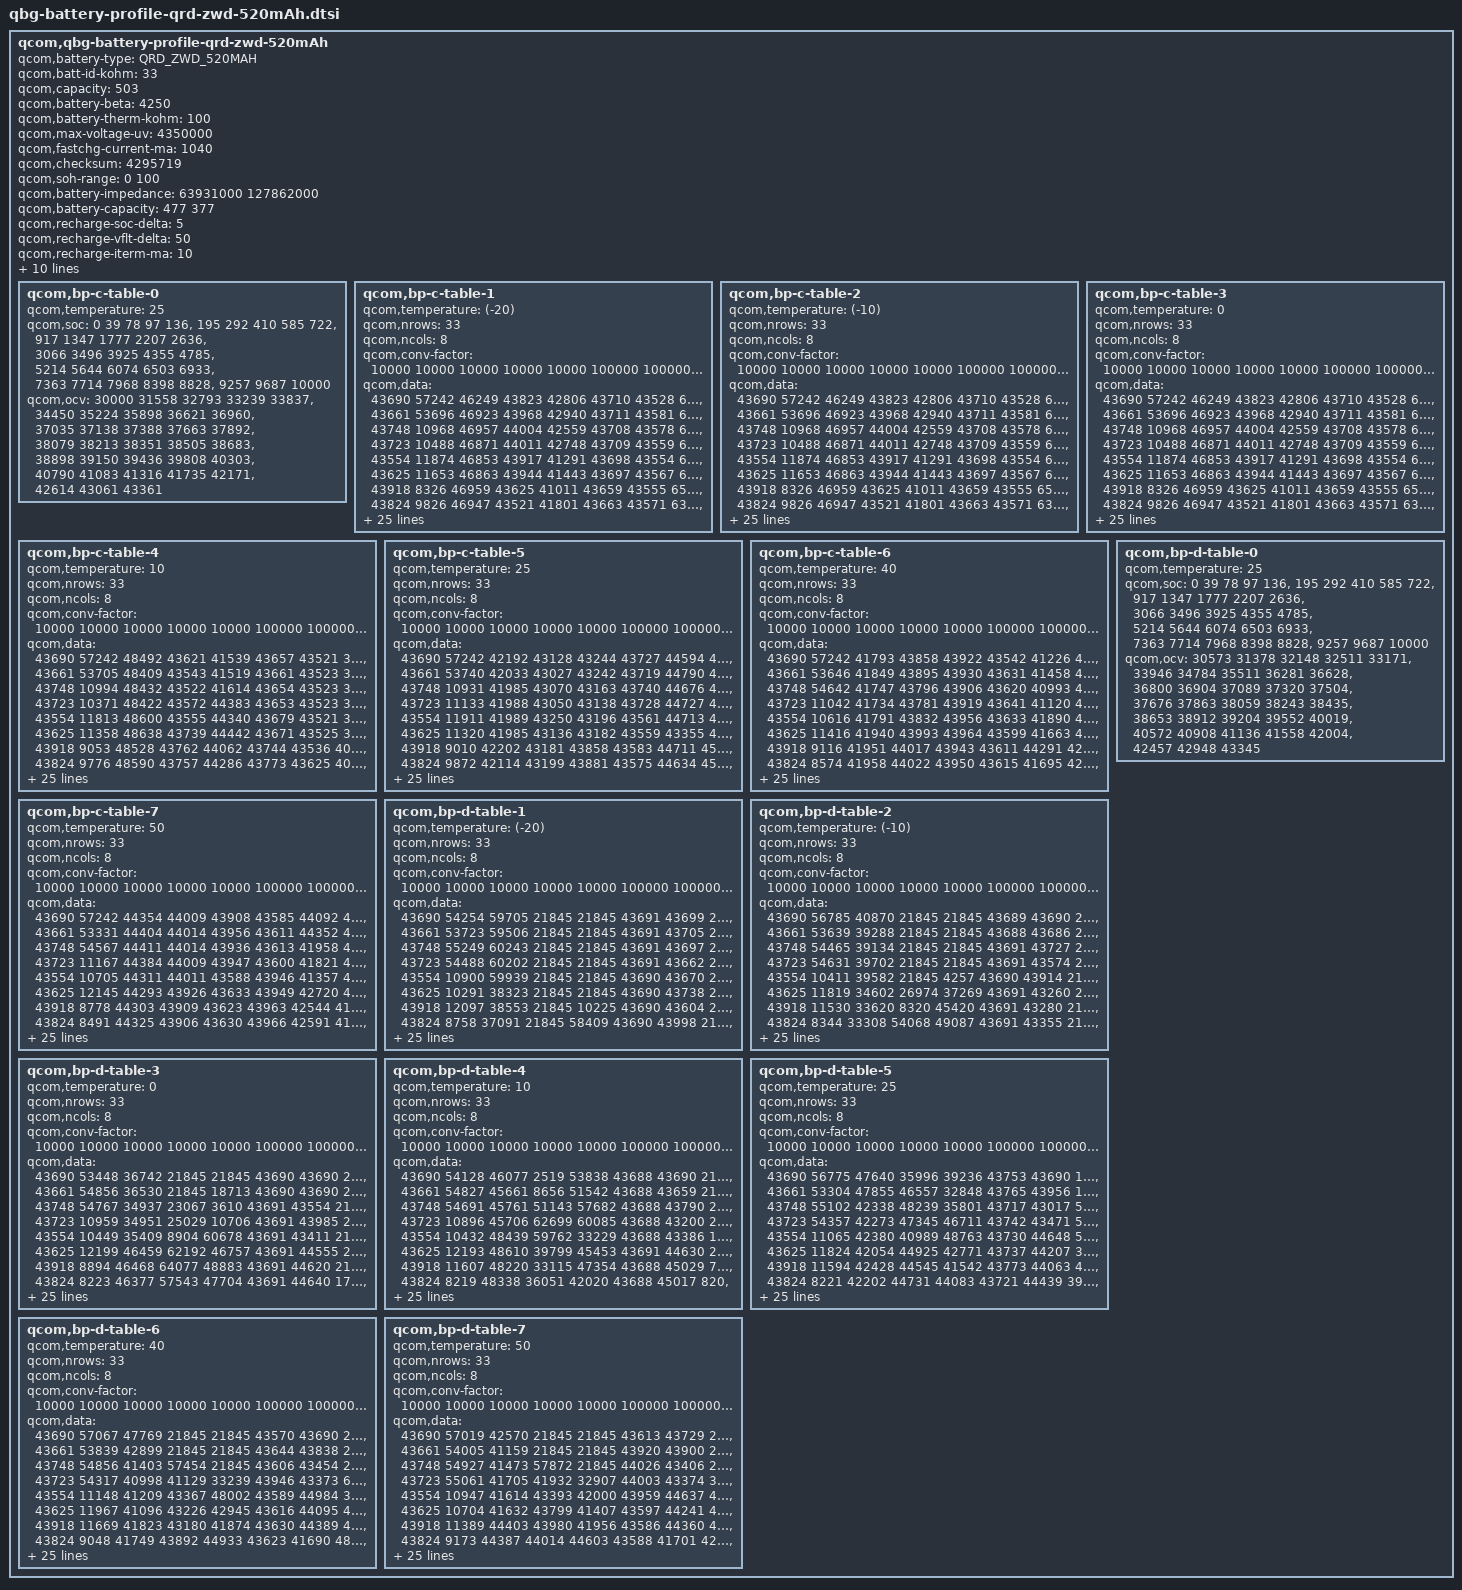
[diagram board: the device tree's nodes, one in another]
qcom,qbg-battery-profile-qrd-zwd-520mAh {
	qcom,battery-type = "QRD_ZWD_520MAH";
	qcom,batt-id-kohm = <33>;
	qcom,capacity = <503>;
	qcom,battery-beta = <4250>;
	qcom,battery-therm-kohm = <100>;
	qcom,max-voltage-uv = <4350000>;
	qcom,fastchg-current-ma = <1040>;
	qcom,checksum = <4295719>; /*@5, 0.005V, 4% */
	qcom,soh-range = <0 100>;
	/* Nominal_Impedance in 10nohm @ SOC 50% 25C* 0:fresh cell, 1: aged cell */
	qcom,battery-impedance = <63931000 127862000>;
	/* Nominal_Capacity in mAh. 0: fresh cell, 1:aged cell */
	qcom,battery-capacity = <477 377>;
	/* SOC delta (in percent) dropped from EOC SOC to enable recharge */
	qcom,recharge-soc-delta =<5>;
	/* vfloat delta (in mV) dropped from regular vfloat in recharge */
	qcom,recharge-vflt-delta =<50>;
	/* Termination current (in mA) in recharge */
	qcom,recharge-iterm-ma = <10>;

	qcom,jeita-fcc-ranges = <0 150 156000
				151 435 1040000
				436 445 800000
				446 450 650000>;

	qcom,jeita-fv-ranges = <0 150 4300000
				151 435 4350000
				436 445 4350000
				446 450 4350000>;

	/* COOL = 15 DegC, WARM = 45 DegC */
	qcom,jeita-soft-thresholds = <0x27c1 0x128c>;
	/* COLD = 0 DegC, HOT = 45.1 DegC */
	qcom,jeita-hard-thresholds = <0x3257 0x127e>;
	/* COOL = 18 DegC, WARM = 44 DegC*/
	qcom,jeita-soft-hys-thresholds = <0x256e 0x131c>;
	qcom,step-jeita-hysteresis = <5 5>;
	qcom,jeita-soft-fcc-ua = <156000 520000>;
	qcom,jeita-soft-fv-uv = <4300000 4300000>;

	qcom,bp-c-table-0 {
		qcom,temperature = <25>;
		qcom,soc = <    0    39    78    97   136>,
			<  195   292   410   585   722>,
			<  917  1347  1777  2207  2636>,
			< 3066  3496  3925  4355  4785>,
			< 5214  5644  6074  6503  6933>,
			< 7363  7714  7968  8398  8828>,
			< 9257  9687 10000>;
		qcom,ocv = <30000 31558 32793 33239 33837>,
			<34450 35224 35898 36621 36960>,
			<37035 37138 37388 37663 37892>,
			<38079 38213 38351 38505 38683>,
			<38898 39150 39436 39808 40303>,
			<40790 41083 41316 41735 42171>,
			<42614 43061 43361>;
	};

	qcom,bp-c-table-1 {
		qcom,temperature = <(-20)>;
		qcom,nrows = <33>;
		qcom,ncols = <8>;
		qcom,conv-factor = <10000 10000 10000 10000 10000 100000 100000 10000>;
		qcom,data = <43690 57242 46249 43823 42806 43710 43528 63481>,
			<43661 53696 46923 43968 42940 43711 43581 61818>,
			<43748 10968 46957 44004 42559 43708 43578 61693>,
			<43723 10488 46871 44011 42748 43709 43559 62219>,
			<43554 11874 46853 43917 41291 43698 43554 62183>,
			<43625 11653 46863 43944 41443 43697 43567 64560>,
			<43918  8326 46959 43625 41011 43659 43555 65029>,
			<43824  9826 46947 43521 41801 43663 43571 63926>,
			<43235  9533 46877 43554 41474 43654 43523 64121>,
			<43128 14970 46226 43714 41666 43679 43530 58694>,
			<43327 15254 46921 43738 41551 43673 43535 64158>,
			<45033 15227 46855 43560 41806 43652 43548 64432>,
			<44123 14462 46153 43581 40975 43649 43625 64304>,
			<41525 14716 46966 43582 41354 43649 43539 64323>,
			<41190 15933 46306 43631 42710 43662 43617 64313>,
			<41296 16266 46933 43136 42601 43656 43916 64487>,
			<42754 16162 46939 44544 42664 43654 43869 64483>,
			<42495 16192 46875 44079 41436 43664 43097 64508>,
			<48041 15555 46710 44477 41240 43669 43267 64440>,
			<47131 15449 46679 44333 42738 43759 44588 64440>,
			<48884 15669 46610 44354 42532 43768 45005 64069>,
			<48294 13014 46812 41619 42535 43764 44263 64146>,
			<48400 13256 46819 41505 42501 43714 44490 58677>,
			<46029 12514 46783 41890 42767 43719 44399 64505>,
			<45503 12744 46805 41837 42275 43716 44515 64740>,
			<46697 14216 46900 41082 47831 43717 44236 62641>,
			<46216 13396 46370 41282 47713 43738 44835 52442>,
			<46474 13648 46400 42707 47876 43739 44653 49493>,
			<35428  3037 35486 42605 47434 43736 43307 57045>,
			<35030  2476 35739 42498 48155 43716 43009 55120>,
			<36483  3592 35625 42702 45888 43770 43194  8928>,
			<36733  3273 35768 44271 46636 43710 43939  9217>,
			<36282  3381 35760 43042 45296 43680 43580 14429>;
	};

	qcom,bp-c-table-2 {
		qcom,temperature = <(-10)>;
		qcom,nrows = <33>;
		qcom,ncols = <8>;
		qcom,conv-factor = <10000 10000 10000 10000 10000 100000 100000 10000>;
		qcom,data = <43690 57242 46249 43823 42806 43710 43528 63481>,
			<43661 53696 46923 43968 42940 43711 43581 61818>,
			<43748 10968 46957 44004 42559 43708 43578 61693>,
			<43723 10488 46871 44011 42748 43709 43559 62219>,
			<43554 11874 46853 43917 41291 43698 43554 62183>,
			<43625 11653 46863 43944 41443 43697 43567 64560>,
			<43918  8326 46959 43625 41011 43659 43555 65029>,
			<43824  9826 46947 43521 41801 43663 43571 63926>,
			<43235  9533 46877 43554 41474 43654 43523 64121>,
			<43128 14970 46226 43714 41666 43679 43530 58694>,
			<43327 15254 46921 43738 41551 43673 43535 64158>,
			<45033 15227 46855 43560 41806 43652 43548 64432>,
			<44123 14462 46153 43581 40975 43649 43625 64304>,
			<41525 14716 46966 43582 41354 43649 43539 64323>,
			<41190 15933 46306 43631 42710 43662 43617 64313>,
			<41296 16266 46933 43136 42601 43656 43916 64487>,
			<42754 16162 46939 44544 42664 43654 43869 64483>,
			<42495 16192 46875 44079 41436 43664 43097 64508>,
			<48041 15555 46710 44477 41240 43669 43267 64440>,
			<47131 15449 46679 44333 42738 43759 44588 64440>,
			<48884 15669 46610 44354 42532 43768 45005 64069>,
			<48294 13014 46812 41619 42535 43764 44263 64146>,
			<48400 13256 46819 41505 42501 43714 44490 58677>,
			<46029 12514 46783 41890 42767 43719 44399 64505>,
			<45503 12744 46805 41837 42275 43716 44515 64740>,
			<46697 14216 46900 41082 47831 43717 44236 62641>,
			<46216 13396 46370 41282 47713 43738 44835 52442>,
			<46474 13648 46400 42707 47876 43739 44653 49493>,
			<35428  3037 35486 42605 47434 43736 43307 57045>,
			<35030  2476 35739 42498 48155 43716 43009 55120>,
			<36483  3592 35625 42702 45888 43770 43194  8928>,
			<36733  3273 35768 44271 46636 43710 43939  9217>,
			<36282  3381 35760 43042 45296 43680 43580 14429>;
	};

	qcom,bp-c-table-3 {
		qcom,temperature = <0>;
		qcom,nrows = <33>;
		qcom,ncols = <8>;
		qcom,conv-factor = <10000 10000 10000 10000 10000 100000 100000 10000>;
		qcom,data = <43690 57242 46249 43823 42806 43710 43528 63481>,
			<43661 53696 46923 43968 42940 43711 43581 61818>,
			<43748 10968 46957 44004 42559 43708 43578 61693>,
			<43723 10488 46871 44011 42748 43709 43559 62219>,
			<43554 11874 46853 43917 41291 43698 43554 62183>,
			<43625 11653 46863 43944 41443 43697 43567 64560>,
			<43918  8326 46959 43625 41011 43659 43555 65029>,
			<43824  9826 46947 43521 41801 43663 43571 63926>,
			<43235  9533 46877 43554 41474 43654 43523 64121>,
			<43128 14970 46226 43714 41666 43679 43530 58694>,
			<43327 15254 46921 43738 41551 43673 43535 64158>,
			<45033 15227 46855 43560 41806 43652 43548 64432>,
			<44123 14462 46153 43581 40975 43649 43625 64304>,
			<41525 14716 46966 43582 41354 43649 43539 64323>,
			<41190 15933 46306 43631 42710 43662 43617 64313>,
			<41296 16266 46933 43136 42601 43656 43916 64487>,
			<42754 16162 46939 44544 42664 43654 43869 64483>,
			<42495 16192 46875 44079 41436 43664 43097 64508>,
			<48041 15555 46710 44477 41240 43669 43267 64440>,
			<47131 15449 46679 44333 42738 43759 44588 64440>,
			<48884 15669 46610 44354 42532 43768 45005 64069>,
			<48294 13014 46812 41619 42535 43764 44263 64146>,
			<48400 13256 46819 41505 42501 43714 44490 58677>,
			<46029 12514 46783 41890 42767 43719 44399 64505>,
			<45503 12744 46805 41837 42275 43716 44515 64740>,
			<46697 14216 46900 41082 47831 43717 44236 62641>,
			<46216 13396 46370 41282 47713 43738 44835 52442>,
			<46474 13648 46400 42707 47876 43739 44653 49493>,
			<35428  3037 35486 42605 47434 43736 43307 57045>,
			<35030  2476 35739 42498 48155 43716 43009 55120>,
			<36483  3592 35625 42702 45888 43770 43194  8928>,
			<36733  3273 35768 44271 46636 43710 43939  9217>,
			<36282  3381 35760 43042 45296 43680 43580 14429>;
	};

	qcom,bp-c-table-4 {
		qcom,temperature = <10>;
		qcom,nrows = <33>;
		qcom,ncols = <8>;
		qcom,conv-factor = <10000 10000 10000 10000 10000 100000 100000 10000>;
		qcom,data = <43690 57242 48492 43621 41539 43657 43521 38680>,
			<43661 53705 48409 43543 41519 43661 43523 38594>,
			<43748 10994 48432 43522 41614 43654 43523 37248>,
			<43723 10371 48422 43572 44383 43653 43523 36920>,
			<43554 11813 48600 43555 44340 43679 43521 37855>,
			<43625 11358 48638 43739 44442 43671 43525 37551>,
			<43918  9053 48528 43762 44062 43744 43536 40160>,
			<43824  9776 48590 43757 44286 43773 43625 40543>,
			<43235  9692 48237 43703 44906 43520 43618 39212>,
			<43128 14873 48213 43705 44843 43596 43541 39122>,
			<43327 15266 48178 43707 44876 43911 43542 38973>,
			<45033 15166 48573 43674 44039 43732 43636 39343>,
			<44123 14390 48234 43753 44459 43720 43602 39340>,
			<41525 14606 48515 43763 44451 43774 43936 38950>,
			<41190 16087 48131 43771 44478 43761 43612 39798>,
			<41296 15966 48129 44766 43333 43555 44865 39146>,
			<42754 16372 48178 44808 43303 43582 41716 39147>,
			<42495 16254 48344 44894 43386 43583 41778 39041>,
			<48041 15566 48382 44265 44719 43583 41024 39092>,
			<47131 15794 48318 44066 44684 43580 42738 39083>,
			<48884 12972 48292 44094 43348 43576 41408 39879>,
			<48294 13237 48266 44091 43386 43559 41929 39494>,
			<48400 12522 48311 44046 43378 43555 44358 39453>,
			<46029 12786 48903 44452 44697 43552 44308 39499>,
			<45503 13879 48958 44482 44557 43556 44354 39883>,
			<46697 13316 49105 44033 44632 43555 44547 39743>,
			<46216  2730 48904 44122 44809 43555 44729 39403>,
			<46474  2683 48987 44530 44243 43552 43348 40812>,
			<35428  2303 48309 44319 44307 43553 43282 37756>,
			<35030  2373 48257 44365 41878 43556 43272 38299>,
			<36483  3847 48266 44614 42982 43730 43221 61356>,
			<36733  3536 48302 43756 47846 43753 43598 57367>,
			<36282   513 48308 43769 42998 43667 43547 58712>;
	};

	qcom,bp-c-table-5 {
		qcom,temperature = <25>;
		qcom,nrows = <33>;
		qcom,ncols = <8>;
		qcom,conv-factor = <10000 10000 10000 10000 10000 100000 100000 10000>;
		qcom,data = <43690 57242 42192 43128 43244 43727 44594 46360>,
			<43661 53740 42033 43027 43242 43719 44790 46504>,
			<43748 10931 41985 43070 43163 43740 44676 46328>,
			<43723 11133 41988 43050 43138 43728 44727 46934>,
			<43554 11911 41989 43250 43196 43561 44713 47092>,
			<43625 11320 41985 43136 43182 43559 43355 46603>,
			<43918  9010 42202 43181 43858 43583 44711 45381>,
			<43824  9872 42114 43199 43881 43575 44634 45547>,
			<43235  9639 42864 43196 43827 43523 44916 45105>,
			<43128 15050 42825 43815 43886 43551 43517 45891>,
			<43327 14849 42844 43778 43903 43551 43504 45943>,
			<45033 15288 42816 43063 43843 43527 41833 45265>,
			<44123 14502 42850 43111 43167 43545 41290 45112>,
			<41525 14773 42853 43072 43137 43543 42860 45186>,
			<41190 16046 42779 43076 43156 43537 42902 45950>,
			<41296 15893 42815 43110 43178 43550 41191 45652>,
			<42754 16367 42968 43125 43180 43525 41810 45630>,
			<42495 16229 42959 43103 43144 43520 41560 45766>,
			<48041 15555 43002 43395 43259 43527 41895 45778>,
			<47131 15793 42935 43463 43063 43538 41747 45679>,
			<48884 15704 42923 43307 43405 43540 41763 45959>,
			<48294 12868 42892 43307 43384 43628 41141 45835>,
			<48400 12454 42939 43297 44789 43622 42133 45224>,
			<46029 12586 42567 43298 43271 43642 42378 46003>,
			<45503 14277 42584 43496 43204 43629 41437 48443>,
			<46697 13820 42930 43089 43138 43547 44463 48615>,
			<46216  2769 42890 43425 43222 43524 44241 48463>,
			<46474  3022 42926 43392 43044 43547 44041 45697>,
			<35428  2477 42573 43487 43008 43538 44505 45590>,
			<35030  3601 42568 43271 43443 43551 44455 45926>,
			<36483  3292 42565 43362 44582 43627 44872 46658>,
			<36733   671 42898 43497 44078 43540 44672 35344>,
			<36282   971 42578 43043 44115 43553 43059 35054>;
	};

	qcom,bp-c-table-6 {
		qcom,temperature = <40>;
		qcom,nrows = <33>;
		qcom,ncols = <8>;
		qcom,conv-factor = <10000 10000 10000 10000 10000 100000 100000 10000>;
		qcom,data = <43690 57242 41793 43858 43922 43542 41226 47804>,
			<43661 53646 41849 43895 43930 43631 41458 42348>,
			<43748 54642 41747 43796 43906 43620 40993 42461>,
			<43723 11042 41734 43781 43919 43641 41120 42491>,
			<43554 10616 41791 43832 43956 43633 41890 42400>,
			<43625 11416 41940 43993 43964 43599 41663 42014>,
			<43918  9116 41951 44017 43943 43611 44291 42227>,
			<43824  8574 41958 44022 43950 43615 41695 42114>,
			<43235  9230 41880 44012 43939 43605 44373 42827>,
			<43128  9555 41884 44008 43598 43947 41001 42763>,
			<43327 15085 41880 44001 43634 43608 41407 42966>,
			<45033 14863 41869 43822 43832 43615 41081 42215>,
			<44123 15106 41899 43815 43801 43614 41253 42212>,
			<41525 14441 41554 43786 43803 43609 42813 42115>,
			<41190 14605 41567 43777 43885 43589 42861 42162>,
			<41296 16114 41590 43795 43899 43590 42201 42152>,
			<42754 16299 41494 43800 43823 43587 42961 42975>,
			<42495 16179 41527 43799 43822 43596 42643 43003>,
			<48041 15598 41517 43884 43824 43595 41122 43000>,
			<47131 15776 41683 43854 43887 43633 41771 42960>,
			<48884 15706 41669 43177 43169 43634 41964 42879>,
			<48294 13225 41675 43179 43218 43647 44345 42118>,
			<48400 12521 41721 43171 43082 43647 44405 42023>,
			<46029 12654 41717 43176 43129 43636 42633 42183>,
			<45503 14091 41718 43879 43781 43599 41290 42936>,
			<46697 13810 41717 43792 44028 43596 41818 42502>,
			<46216  2570 41674 43793 43995 43596 41893 42610>,
			<46474  2866 41675 43883 43811 43587 41495 42924>,
			<35428  2531 41664 43898 43794 43597 41723 42952>,
			<35030  4014 41680 43842 43866 43593 41672 42872>,
			<36483  3181 41512 43179 43251 43595 44369 42022>,
			<36733   553 41478 43856 43305 43586 44882 47752>,
			<36282   769 41691 43829 43494 43964 43315 42352>;
	};

	qcom,bp-c-table-7 {
		qcom,temperature = <50>;
		qcom,nrows = <33>;
		qcom,ncols = <8>;
		qcom,conv-factor = <10000 10000 10000 10000 10000 100000 100000 10000>;
		qcom,data = <43690 57242 44354 44009 43908 43585 44092 41271>,
			<43661 53331 44404 44014 43956 43611 44352 41434>,
			<43748 54567 44411 44014 43936 43613 41958 41455>,
			<43723 11167 44384 44009 43947 43600 41821 41370>,
			<43554 10705 44311 44011 43588 43946 41357 41376>,
			<43625 12145 44293 43926 43633 43949 42720 41075>,
			<43918  8778 44303 43909 43623 43963 42544 41012>,
			<43824  8491 44325 43906 43630 43966 42591 41177>,
			<43235  9466 44504 43966 43616 43915 41225 41187>,
			<43128  9497 44484 43610 43617 43930 41179 41144>,
			<43327 15011 44535 43606 43550 43912 41989 41808>,
			<45033 15053 44537 43955 43970 43913 41787 40978>,
			<44123 15300 44513 43952 43974 43913 41169 40975>,
			<41525 14372 44443 43913 43971 43913 42660 41017>,
			<41190 14810 44467 43930 43811 43958 42710 41012>,
			<41296 16010 44454 43921 43801 43964 42581 40978>,
			<42754 15991 44120 43926 44000 43961 42210 41095>,
			<42495 16340 44149 44013 44011 43939 42949 41149>,
			<48041 15515 44140 44025 44027 43950 41275 41099>,
			<47131 15787 44057 43983 43999 43605 41137 41196>,
			<48884 15704 44044 43985 43780 43606 41552 40993>,
			<48294 13216 44086 43810 43179 43600 44381 41032>,
			<48400 12541 44095 43998 43233 43606 44468 41400>,
			<46029 12623 44091 43983 43165 43607 41877 41033>,
			<45503 14102 44094 43926 43932 43938 40990 41754>,
			<46697 13762 44082 43917 43936 43942 41929 41950>,
			<46216  2585 44081 43928 43959 43938 41957 41785>,
			<46474  2817 44042 44001 43904 43948 40992 41832>,
			<35428  2548 44033 44031 44024 43948 41100 41133>,
			<35030  4021 44063 44031 43810 43950 41580 41191>,
			<36483  3150 44143 43976 43892 43945 41648 41056>,
			<36733   561 44152 43986 43218 43950 44124 41273>,
			<36282   791 44033 43971 43227 44003 44622 41470>;
	};

	qcom,bp-d-table-0 {
		qcom,temperature = <25>;
		qcom,soc = <    0    39    78    97   136>,
			<  195   292   410   585   722>,
			<  917  1347  1777  2207  2636>,
			< 3066  3496  3925  4355  4785>,
			< 5214  5644  6074  6503  6933>,
			< 7363  7714  7968  8398  8828>,
			< 9257  9687 10000>;
		qcom,ocv = <30573 31378 32148 32511 33171>,
			<33946 34784 35511 36281 36628>,
			<36800 36904 37089 37320 37504>,
			<37676 37863 38059 38243 38435>,
			<38653 38912 39204 39552 40019>,
			<40572 40908 41136 41558 42004>,
			<42457 42948 43345>;
	};

	qcom,bp-d-table-1 {
		qcom,temperature = <(-20)>;
		qcom,nrows = <33>;
		qcom,ncols = <8>;
		qcom,conv-factor = <10000 10000 10000 10000 10000 100000 100000 10000>;
		qcom,data = <43690 54254 59705 21845 21845 43691 43699 21845>,
			<43661 53723 59506 21845 21845 43691 43705 21845>,
			<43748 55249 60243 21845 21845 43691 43697 21845>,
			<43723 54488 60202 21845 21845 43691 43662 21845>,
			<43554 10900 59939 21845 21845 43690 43670 21845>,
			<43625 10291 38323 21845 21845 43690 43738 21845>,
			<43918 12097 38553 21845 10225 43690 43604 21845>,
			<43824  8758 37091 21845 58409 43690 43998 21845>,
			<43235  8578 37390 21845 36992 43690 43864 21845>,
			<43128  9920 40220 21845 40738 43691 43191 21845>,
			<43327 10090 40216 21845 40568 43691 43229 21845>,
			<45033  9514 40151 24910 33285 43691 43017 21845>,
			<44123 14884 40581  3528 35824 43691 43200 21845>,
			<41525 15304 40648 12876 47073 43691 43232 21845>,
			<41190 14500 39183 14356 45543 43691 43146 21845>,
			<41296 14345 40480  9894 45193 43691 43862 21845>,
			<42754 14750 40936 11355 46008 43691 43871 21845>,
			<42495 14702 40544 10366 45750 43691 43862 21845>,
			<48041 16122 40638 55123 48428 43691 43841 21845>,
			<47131 15947 40911 54106 48220 43691 43889 21845>,
			<48884 16340 40499 56417 48328 43691 43901 21845>,
			<48294 15491 40593 55745 48308 43691 43875 21845>,
			<48400 15450 40879 56134 48972 43691 43872 21845>,
			<46029 15694 40788 56203 48974 43691 43899 21845>,
			<45503 13236 40660 56235 48334 43691 43178 21845>,
			<46697 12293 40931 55627 48468 43691 43256 21845>,
			<46216 13989 40843 56529 45879 43691 43249 21845>,
			<46474 14306 40874 54079 45366 43691 43230 21845>,
			<35428  2786 40929 12141 36437 43691 44553 21845>,
			<35030  2209 40450  9760 36155 43691 43205 21845>,
			<36483  3734 40551 12780 36661 43691 43842 21845>,
			<36733  3481 40093  7190 46961 43691 43842 21845>,
			<36282   886 40262 24682 48397 43691 43863 21845>;
	};

	qcom,bp-d-table-2 {
		qcom,temperature = <(-10)>;
		qcom,nrows = <33>;
		qcom,ncols = <8>;
		qcom,conv-factor = <10000 10000 10000 10000 10000 100000 100000 10000>;
		qcom,data = <43690 56785 40870 21845 21845 43689 43690 21845>,
			<43661 53639 39288 21845 21845 43688 43686 21845>,
			<43748 54465 39134 21845 21845 43691 43727 21845>,
			<43723 54631 39702 21845 21845 43691 43574 21845>,
			<43554 10411 39582 21845  4257 43690 43914 21845>,
			<43625 11819 34602 26974 37269 43691 43260 21845>,
			<43918 11530 33620  8320 45420 43691 43280 21845>,
			<43824  8344 33308 54068 49087 43691 43355 21845>,
			<43235  9830 33695 55743 48755 43691 44747 21845>,
			<43128  9379 33734 56293 48564 43691 44772 21845>,
			<43327  9601 33715 56096 45294 43691 44729 21845>,
			<45033 15095 33664 52620 48552 43691 43130 21845>,
			<44123 15247 33717 62952 47594 43691 43213 21845>,
			<41525 15201 33336 62243 47621 43691 43240 21845>,
			<41190 14543 33335 63815 42243 43691 43144 21845>,
			<41296 14419 33311 58803 42064 43691 43185 21845>,
			<42754 14624 33362 57662 42043 43691 43147 21845>,
			<42495 16063 33675 60766 42235 43691 43196 21505>,
			<48041 15880 33737 61161 42833 43688 43188 20700>,
			<47131 16280 33401 60355 42849 43688 43175 23937>,
			<48884 16255 33570 38384 42753 43688 43192 24481>,
			<48294 15419 33384 38819 42855 43688 43169 22640>,
			<48400 15659 33339 38632 42216 43688 43164 22529>,
			<46029 12829 33334 38633 42487 43688 43059 24261>,
			<45503 12420 33690 38502 47968 43691 43015 23934>,
			<46697 12667 33618 38362 47447 43691 43046 22349>,
			<46216 13552 33788 60619 46526 43691 44565 21845>,
			<46474 13641 33355 57366 36553 43691 44914 21845>,
			<35428  2987 32907 58944 34908 43691 43213 21845>,
			<35030  2069 33751 64791 35577 43691 43239 21845>,
			<36483  3701 33677 52525 46855 43691 43136 21845>,
			<36733  3549 33573 53471 45549 43691 43876 21845>,
			<36282   878 33000  9066 45827 43691 43835 21845>;
	};

	qcom,bp-d-table-3 {
		qcom,temperature = <0>;
		qcom,nrows = <33>;
		qcom,ncols = <8>;
		qcom,conv-factor = <10000 10000 10000 10000 10000 100000 100000 10000>;
		qcom,data = <43690 53448 36742 21845 21845 43690 43690 21845>,
			<43661 54856 36530 21845 18713 43690 43690 21845>,
			<43748 54767 34937 23067  3610 43691 43554 21845>,
			<43723 10959 34951 25029 10706 43691 43985 21845>,
			<43554 10449 35409  8904 60678 43691 43411 21845>,
			<43625 12199 46459 62192 46757 43691 44555 21845>,
			<43918  8894 46468 64077 48883 43691 44620 21078>,
			<43824  8223 46377 57543 47704 43691 44640 17971>,
			<43235 10190 46102 59746 42343 43691 44974 19234>,
			<43128  9229 46556 61372 47241 43691 44572 20215>,
			<43327  9483 46343 60865 47384 43691 43339 19467>,
			<45033 15059 46362 38238 42785 43691 43042 32143>,
			<44123 15241 46544 37732 41001 43691 43261 26154>,
			<41525 15206 46554 40612 41849 43688 43153 28185>,
			<41190 14383 46108 33863 41821 43688 43218  5277>,
			<41296 14727 46482 32977 41091 43688 43222  5027>,
			<42754 14698 46588 35951 41140 43688 43223  7898>,
			<42495 16108 46536 35289 41796 43688 43222  6792>,
			<48041 15977 46520 35522 41801 43688 43153  1776>,
			<47131 16356 46513 46216 41762 43688 43258   607>,
			<48884 16196 46519 46735 41763 43688 43237  3111>,
			<48294 15382 46515 45445 41849 43688 43045  3941>,
			<48400 15712 46495 45262 41449 43688 43111  3214>,
			<46029 13234 46487 45243 42826 43688 43128   716>,
			<45503 12291 46511 46761 47791 43688 43106  1589>,
			<46697 14209 46504 35167 45822 43688 44270  4509>,
			<46216 13729 46190 36856 35348 43688 44977 27890>,
			<46474  2738 46092 36017 35282 43688 43314 24610>,
			<35428  3050 46498 32977 46316 43688 43191 26253>,
			<35030  2490 46149 39096 46970 43688 43138 32343>,
			<36483  3978 46198 38556 45388 43688 43187 29988>,
			<36733  3375 46157 57970 48224 43691 43888 17212>,
			<36282   822 46464 63920 48776 43691 43786 23160>;
	};

	qcom,bp-d-table-4 {
		qcom,temperature = <10>;
		qcom,nrows = <33>;
		qcom,ncols = <8>;
		qcom,conv-factor = <10000 10000 10000 10000 10000 100000 100000 10000>;
		qcom,data = <43690 54128 46077  2519 53838 43688 43690 21845>,
			<43661 54827 45661  8656 51542 43688 43659 21845>,
			<43748 54691 45761 51143 57682 43688 43790 21845>,
			<43723 10896 45706 62699 60085 43688 43200 21845>,
			<43554 10432 48439 59762 33229 43688 43386 17457>,
			<43625 12193 48610 39799 45453 43691 44630 27786>,
			<43918 11607 48220 33115 47354 43688 45029  7998>,
			<43824  8219 48338 36051 42020 43688 45017   820>,
			<43235 10028 48140 35776 42995 43688 44832  2762>,
			<43128  9339 48346 35267 42247 43688 44637  4029>,
			<43327  9521 48367 36552 42842 43688 43477  3804>,
			<45033 15077 48967 46812 44318 43688 43063 14644>,
			<44123 15273 48338 49001 44468 43688 43034  9139>,
			<41525 15178 48273 47709 44290 43689 43120 11219>,
			<41190 14388 48373 42987 44406 43689 43128 53367>,
			<41296 14742 48383 40999 44363 43694 43026 57248>,
			<42754 14697 48348 41702 44388 43694 43055 50523>,
			<42495 16110 48142 44095 44399 43695 43205 49438>,
			<48041 15980 48255 44550 41606 43693 43144 52530>,
			<47131 16368 48355 43408 41587 43683 43872 52912>,
			<48884 15542 48187 43352 41510 43682 43045 51259>,
			<48294 15780 48325 44789 41939 43682 43076 51254>,
			<48400 12954 48352 44948 41229 43682 43425 51479>,
			<46029 13266 48322 44308 42578 43682 43492 52384>,
			<45503 12374 48284 41831 42146 43687 43402 49761>,
			<46697 13498 48178 42588 46614 43733 44203 54838>,
			<46216 13800 48329 42966 46744 43775 43387 54941>,
			<46474  2729 48285 42844 45212 43670 43205 53550>,
			<35428  2916 48256 48838 47420 43727 44660 54569>,
			<35030  2517 48289 47421 48782 43749 43323 10389>,
			<36483  4085 48284 48957 47386 43663 43219 12185>,
			<36733  3391 48244 47001 48104 43690 43140  8708>,
			<36282   990 48639 35657 42431 43690 43025  8667>;
	};

	qcom,bp-d-table-5 {
		qcom,temperature = <25>;
		qcom,nrows = <33>;
		qcom,ncols = <8>;
		qcom,conv-factor = <10000 10000 10000 10000 10000 100000 100000 10000>;
		qcom,data = <43690 56775 47640 35996 39236 43753 43690 15573>,
			<43661 53304 47855 46557 32848 43765 43956 10253>,
			<43748 55102 42338 48239 35801 43717 43017 50882>,
			<43723 54357 42273 47345 46711 43742 43471 52003>,
			<43554 11065 42380 40989 48763 43730 44648 58416>,
			<43625 11824 42054 44925 42771 43737 44207 38198>,
			<43918 11594 42428 44545 41542 43773 44063 40239>,
			<43824  8221 42202 44731 44083 43721 44439 39102>,
			<43235 10003 42183 43277 44233 43743 44478 33808>,
			<43128  9662 42129 43374 41662 43730 44883 39673>,
			<43327  9578 42226 43484 44208 43740 45006 34565>,
			<45033 14978 42226 43019 43088 43735 45012 36333>,
			<44123 14923 42170 43049 43121 43558 44921 36769>,
			<41525 15202 42123 43224 43130 43570 44816 35310>,
			<41190 14378 42841 43218 43011 43530 44193 35657>,
			<41296 14726 42146 43054 43118 43529 44287 35416>,
			<42754 14669 42166 43020 43468 43533 44124 35454>,
			<42495 15873 42841 43124 43356 43527 44401 35396>,
			<48041 16329 42829 43083 43335 43551 44464 35490>,
			<47131 15497 42853 43118 43270 43525 44880 46492>,
			<48884 15447 42848 43024 43485 43522 45041 46126>,
			<48294 12970 42862 43101 43301 43527 44284 46095>,
			<48400 13198 42857 43405 43329 43524 44089 46571>,
			<46029 12330 42856 43512 44619 43527 44882 35379>,
			<45503 14073 42782 44689 44327 43542 44079 36491>,
			<46697 13526 42846 44961 41473 43545 44550 35942>,
			<46216 13670 42845 44615 44499 43522 44966 36674>,
			<46474  2586 42841 44651 44273 43531 45043 36792>,
			<35428  2300 42861 44791 44854 43572 45026 36397>,
			<35030  3774 42160 44688 45053 43530 44922 36380>,
			<36483  3955 42148 43389 44615 43574 45012 36574>,
			<36733  3438 42949 43093 44689 43553 43286 35272>,
			<36282  1019 42507 43231 43269 43733 43145 34830>;
	};

	qcom,bp-d-table-6 {
		qcom,temperature = <40>;
		qcom,nrows = <33>;
		qcom,ncols = <8>;
		qcom,conv-factor = <10000 10000 10000 10000 10000 100000 100000 10000>;
		qcom,data = <43690 57067 47769 21845 21845 43570 43690 21845>,
			<43661 53839 42899 21845 21845 43644 43838 21845>,
			<43748 54856 41403 57454 21845 43606 43454 21845>,
			<43723 54317 40998 41129 33239 43946 43373 61234>,
			<43554 11148 41209 43367 48002 43589 44984 35138>,
			<43625 11967 41096 43226 42945 43616 44095 46219>,
			<43918 11669 41823 43180 41874 43630 44389 45999>,
			<43824  9048 41749 43892 44933 43623 41690 48833>,
			<43235 10144 41778 43804 43114 43639 41908 48100>,
			<43128  9239 41728 43795 43479 43585 44107 47948>,
			<43327  9505 41786 43786 43075 43610 44180 48058>,
			<45033  9588 41940 44027 43821 43584 44327 42070>,
			<44123 14885 41933 44026 43834 43602 41639 42001>,
			<41525 15317 41875 44030 43834 43605 41520 42196>,
			<41190 14575 41879 44019 43836 43614 41513 42216>,
			<41296 14783 41864 43968 43847 43614 41689 42201>,
			<42754 14674 41889 43817 43105 43602 41503 42374>,
			<42495 15995 41890 43823 43409 43612 44307 42451>,
			<48041 16184 41556 43813 43130 43608 44329 42054>,
			<47131 15612 41592 43988 43161 43588 44038 42160>,
			<48884 15773 41598 43818 43849 43610 44100 42856>,
			<48294 12956 41574 43808 43896 43591 44422 42776>,
			<48400 13303 41572 43838 43849 43596 44124 42875>,
			<46029 12397 41597 43781 43223 43639 44268 41991>,
			<45503 13834 41547 43150 43379 43623 44279 47665>,
			<46697 13355 41564 43145 43321 43541 44616 47660>,
			<46216 13681 41554 43144 43101 43630 44815 47798>,
			<46474  2660 41556 43191 43064 43618 44186 42256>,
			<35428  2264 41918 43880 43248 43619 44661 42488>,
			<35030  3712 41869 43886 43162 43620 44830 42465>,
			<36483  3907 41881 43801 43197 43647 44866 42472>,
			<36733  3347 41872 43818 43171 43594 44930 42372>,
			<36282   944 41885 44031 43171 43596 43325 42378>;
	};

	qcom,bp-d-table-7 {
		qcom,temperature = <50>;
		qcom,nrows = <33>;
		qcom,ncols = <8>;
		qcom,conv-factor = <10000 10000 10000 10000 10000 100000 100000 10000>;
		qcom,data = <43690 57019 42570 21845 21845 43613 43729 21845>,
			<43661 54005 41159 21845 21845 43920 43900 21845>,
			<43748 54927 41473 57872 21845 44026 43406 21845>,
			<43723 55061 41705 41932 32907 44003 43374 38047>,
			<43554 10947 41614 43393 42000 43959 44637 45330>,
			<43625 10704 41632 43799 41407 43597 44241 48273>,
			<43918 11389 44403 43980 41956 43586 44360 47477>,
			<43824  9173 44387 44014 44603 43588 41701 42007>,
			<43235  9780 44299 43934 43147 43949 41947 41303>,
			<43128  9417 44322 43907 43177 43955 44502 41232>,
			<43327  9720 44501 43956 43144 43953 44166 41238>,
			<45033  9472 44484 43947 43928 43912 41837 40992>,
			<44123 15101 44531 43615 44006 43905 41916 41180>,
			<41525 15332 44437 43608 43971 43918 41522 41159>,
			<41190 14512 44420 43600 43977 43959 41978 41189>,
			<41296 14427 44467 43951 43812 43912 41863 41157>,
			<42754 14659 44449 43954 43238 43919 41492 41355>,
			<42495 15986 44118 43956 43134 43912 44352 41264>,
			<48041 16191 44096 43963 43243 43959 44112 41026>,
			<47131 15604 44106 43967 43880 43919 44325 41161>,
			<48884 15850 44147 43954 43992 43959 41631 41121>,
			<48294 13034 44156 43913 44028 43961 41858 41808>,
			<48400 13261 44156 43907 43978 43938 41536 41120>,
			<46029 12410 44157 43927 43903 43600 44288 40960>,
			<45503 13834 44108 43989 43081 43590 44239 42684>,
			<46697 13527 44103 43835 43070 43584 44220 41293>,
			<46216 13691 44120 43968 43145 43586 44824 41459>,
			<46474  2667 44124 44007 43901 43586 44832 41052>,
			<35428  2241 44449 44003 43832 43591 44094 40982>,
			<35030  3723 44465 43924 43973 43614 44524 41013>,
			<36483  3956 44425 43931 44016 43603 44395 40995>,
			<36733  3342 44416 43915 44027 43607 41651 41183>,
			<36282   605 44420 43953 44028 43605 44380 41153>;
	};
};
